# STM32WB55 register map
File version: 2.0
CPU: CM4 r0p1, little endian, MPU, FPU, 4 interrupt priority bits
Registers are 32-bit, read-write, reset 0x0 unless marked. A register's access mark holds for its fields unless they carry their own. Offsets are from the block's base; [hi:lo] are bit positions; {n}, {i} and the like mark numbered series; 'fields as' and 'values as' point back to an identical list.

## GPIOH — General-purpose I/Os
Base 0x48001C00
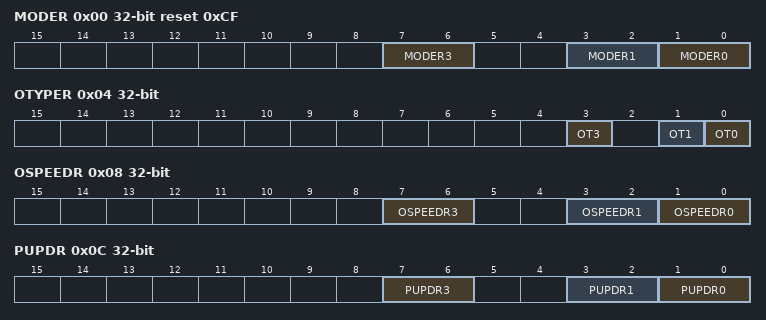
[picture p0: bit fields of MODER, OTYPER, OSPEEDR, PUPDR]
0x00 MODER reset 0xCF — GPIO port mode register
  [all] fields
    0=Input mode (reset state); 1=Output (General purpose output mode); 2=Alternate function mode; 3=Analog mode
  [7:6] MODER3 — Port x configuration bits (y = 0..15)
  [3:2] MODER1 — Port x configuration bits (y = 0..15)
  [1:0] MODER0 — Port x configuration bits (y = 0..15)
0x04 OTYPER — GPIO port output type register
  [all] fields
    0=PushPull (Output push-pull (reset state)); 1=OpenDrain (Output open-drain)
  [3] OT3 — Port x configuration bits (y = 0..15)
  [1] OT1 — Port x configuration bits (y = 0..15)
  [0] OT0 — Port x configuration bits (y = 0..15)
0x08 OSPEEDR — GPIO port output speed register
  [all] fields
    0=LowSpeed; 1=MediumSpeed; 2=HighSpeed; 3=VeryHighSpeed
  [7:6] OSPEEDR3 — Port x configuration bits (y = 0..15)
  [3:2] OSPEEDR1 — Port x configuration bits (y = 0..15)
  [1:0] OSPEEDR0 — Port x configuration bits (y = 0..15)
0x0C PUPDR — GPIO port pull-up/pull-down register
  [all] fields
    0=Floating (No pull-up, pull-down); 1=PullUp; 2=PullDown
  [7:6] PUPDR3 — Port x configuration bits (y = 0..15)
  [3:2] PUPDR1 — Port x configuration bits (y = 0..15)
  [1:0] PUPDR0 — Port x configuration bits (y = 0..15)
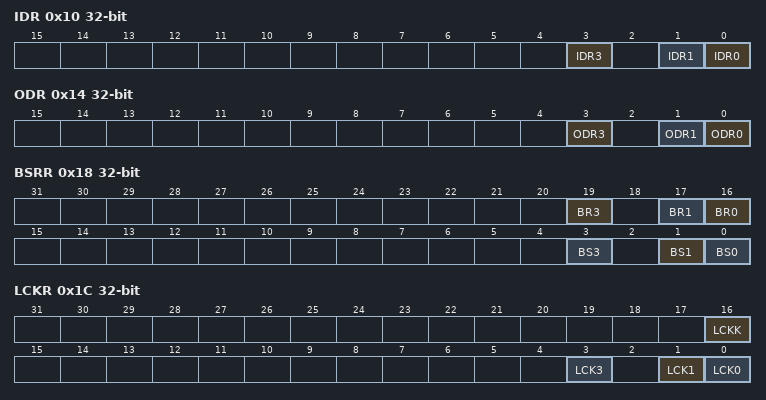
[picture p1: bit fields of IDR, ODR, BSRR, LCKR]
0x10 IDR ro — GPIO port input data register
  [all] fields
    0=Low (Input is logic low); 1=High (Input is logic high)
  [3] IDR3 — Port input data (y = 0..15)
  [1] IDR1 — Port input data (y = 0..15)
  [0] IDR0 — Port input data (y = 0..15)
0x14 ODR — GPIO port output data register
  [all] fields
    0=Low (Set output to logic low); 1=High (Set output to logic high)
  [3] ODR3 — Port output data (y = 0..15)
  [1] ODR1 — Port output data (y = 0..15)
  [0] ODR0 — Port output data (y = 0..15)
0x18 BSRR wo — GPIO port bit set/reset register
  [19] BR3 — Port x reset bit y (y = 0..15)
    1=Resets the corresponding ODRx bit
  [17] BR1 — Port x reset bit y (y = 0..15)
    1=Resets the corresponding ODRx bit
  [16] BR0 — Port x set bit y (y= 0..15)
    1=Resets the corresponding ODRx bit
  [3] BS3 — Port x set bit y (y= 0..15)
    1=Set (Sets the corresponding ODRx bit)
  [1] BS1 — Port x set bit y (y= 0..15)
    1=Set (Sets the corresponding ODRx bit)
  [0] BS0 — Port x set bit y (y= 0..15)
    1=Set (Sets the corresponding ODRx bit)
0x1C LCKR — GPIO port configuration lock register
  [16] LCKK — Port x lock bit y (y= 0..15)
    0=NotActive (Port configuration lock key not active); 1=Active (Port configuration lock key active)
  [3] LCK3 — Port x lock bit y (y= 0..15)
    0=Unlocked (Port configuration not locked); 1=Locked (Port configuration locked)
  [1] LCK1 — Port x lock bit y (y= 0..15)
    values as LCK3
  [0] LCK0 — Port x lock bit y (y= 0..15)
    values as LCK3
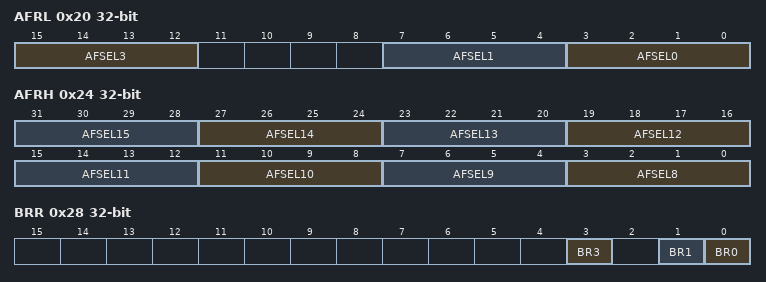
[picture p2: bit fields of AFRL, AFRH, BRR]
0x20 AFRL — GPIO alternate function low register
  [15:12] AFSEL3 — Alternate function selection for port x bit y (y = 0..7)
  [7:4] AFSEL1 — Alternate function selection for port x bit y (y = 0..7)
  [3:0] AFSEL0 — Alternate function selection for port x bit y (y = 0..7)
0x24 AFRH — GPIO alternate function high register
  [4n-29:4n-32] AFSEL{n} (n=8..15) — Alternate function selection for port x bit y (y = 8..15)
0x28 BRR wo — port bit reset register
  [all] fields
    0=No action on the corresponding ODx bit; 1=Reset the ODx bit
  [3] BR3 — Port Reset bit
  [1] BR1 — Port Reset bit
  [0] BR0 — Port Reset bit

## DBGMCU — Debug support
Base 0xE0042000
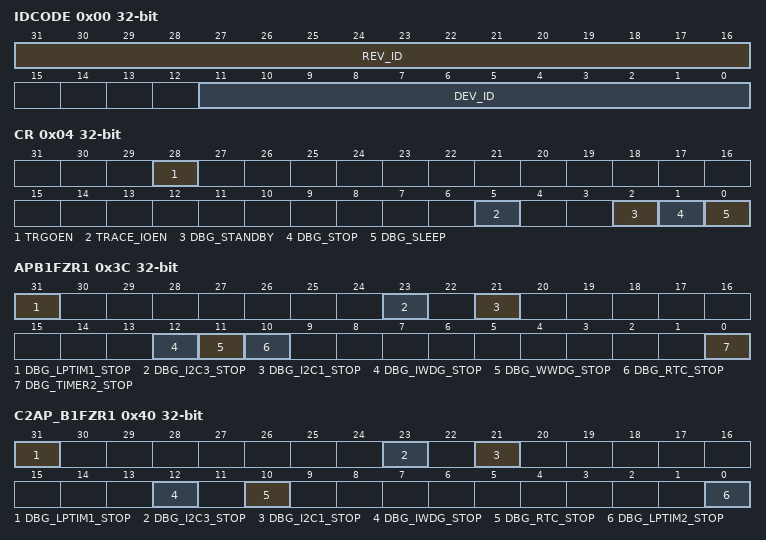
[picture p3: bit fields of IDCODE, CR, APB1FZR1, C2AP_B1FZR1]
0x00 IDCODE ro — MCU Device ID Code Register
  [31:16] REV_ID — Revision Identifier
  [11:0] DEV_ID — Device Identifier
0x04 CR — Debug MCU Configuration Register
  [28] TRGOEN — External trigger output enable
  [5] TRACE_IOEN — Trace port and clock enable
  [2] DBG_STANDBY — Debug Standby Mode
  [1] DBG_STOP — Debug Stop Mode
  [0] DBG_SLEEP — Debug Sleep Mode
0x3C APB1FZR1 — APB1 Low Freeze Register CPU1
  [31] DBG_LPTIM1_STOP — Debug LPTIM1 stopped when Core is halted
  [23] DBG_I2C3_STOP — Debug I2C3 SMBUS timeout stopped when core is halted
  [21] DBG_I2C1_STOP — Debug I2C1 SMBUS timeout stopped when Core is halted
  [12] DBG_IWDG_STOP — IWDG counter stopped when core is halted
  [11] DBG_WWDG_STOP — WWDG counter stopped when core is halted
  [10] DBG_RTC_STOP — RTC counter stopped when core is halted
  [0] DBG_TIMER2_STOP — Debug Timer 2 stopped when Core is halted
0x40 C2AP_B1FZR1 — APB1 Low Freeze Register CPU2
  [31] DBG_LPTIM1_STOP — LPTIM1 counter stopped when core is halted
  [23] DBG_I2C3_STOP — I2C3 SMBUS timeout stopped when core is halted
  [21] DBG_I2C1_STOP — I2C1 SMBUS timeout stopped when core is halted
  [12] DBG_IWDG_STOP — IWDG stopped when core is halted
  [10] DBG_RTC_STOP — RTC counter stopped when core is halted
  [0] DBG_LPTIM2_STOP — LPTIM2 counter stopped when core is halted
0x44 APB1FZR2 — APB1 High Freeze Register CPU1
  [5] DBG_LPTIM2_STOP — LPTIM2 counter stopped when core is halted
0x48 C2APB1FZR2 — APB1 High Freeze Register CPU2
  [5] DBG_LPTIM2_STOP — LPTIM2 counter stopped when core is halted
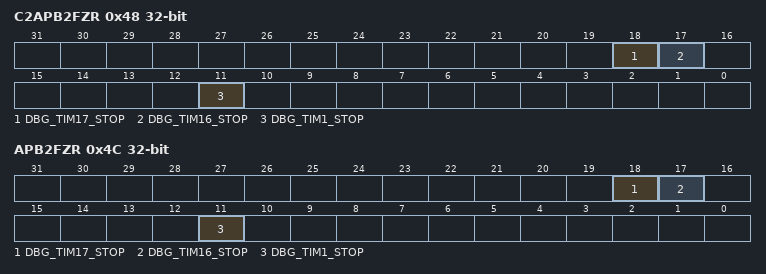
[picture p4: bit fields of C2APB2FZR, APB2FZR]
0x48 C2APB2FZR (alternate view of C2APB1FZR2) — APB2 Freeze Register CPU2
  [18] DBG_TIM17_STOP — TIM17 counter stopped when core is halted
  [17] DBG_TIM16_STOP — TIM16 counter stopped when core is halted
  [11] DBG_TIM1_STOP — TIM1 counter stopped when core is halted
0x4C APB2FZR — APB2 Freeze Register CPU1
  fields as C2APB2FZR
